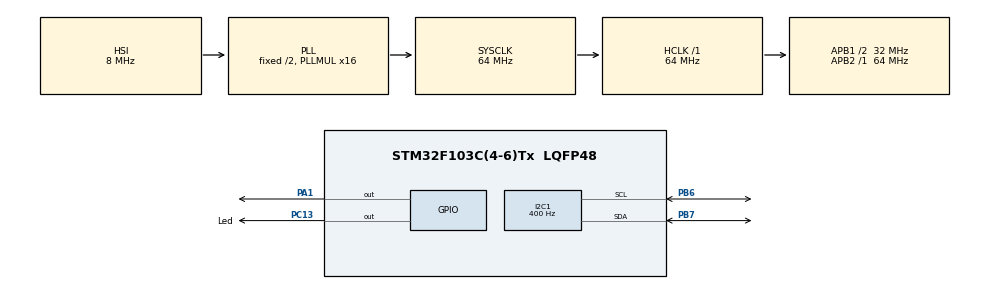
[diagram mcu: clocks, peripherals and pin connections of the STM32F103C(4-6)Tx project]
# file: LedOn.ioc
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I2C1.ClockSpeed=400
Mcu.Family=STM32F1
Mcu.Name=STM32F103C(4-6)Tx
Mcu.Package=LQFP48
NVIC.PriorityGroup=NVIC_PRIORITYGROUP_4
PA1.PinState=GPIO_PIN_SET
PA1.Signal=GPIO_Output
PB6.Mode=I2C
PB6.Signal=I2C1_SCL
PB7.Mode=I2C
PB7.Signal=I2C1_SDA
PC13-TAMPER-RTC.GPIO_Label=Led
PC13-TAMPER-RTC.GPIO_PuPd=GPIO_PULLUP
PC13-TAMPER-RTC.GPIO_Speed=GPIO_SPEED_FREQ_HIGH
PC13-TAMPER-RTC.PinState=GPIO_PIN_SET
PC13-TAMPER-RTC.Signal=GPIO_Output
ProjectManager.HeapSize=0x200
ProjectManager.StackSize=0x400
ProjectManager.TargetToolchain=MDK-ARM V5.32
RCC.AHBFreq_Value=64000000
RCC.APB1CLKDivider=RCC_HCLK_DIV2
RCC.APB1Freq_Value=32000000
RCC.APB1TimFreq_Value=64000000
RCC.APB2Freq_Value=64000000
RCC.APB2TimFreq_Value=64000000
RCC.HCLKFreq_Value=64000000
RCC.PLLMUL=RCC_PLL_MUL16
RCC.SYSCLKFreq_VALUE=64000000
RCC.SYSCLKSource=RCC_SYSCLKSOURCE_PLLCLK
RCC.USBFreq_Value=64000000
VP_SYS_VS_ND.Mode=No_Debug
board=custom

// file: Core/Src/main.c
/* USER CODE BEGIN Header */
/**
  ******************************************************************************
  * @file           : main.c
  * @brief          : Main program body
  ******************************************************************************
  * @attention
  *
  * Copyright (c) 2023 STMicroelectronics.
  * All rights reserved.
  *
  * This software is licensed under terms that can be found in the LICENSE file
  * in the root directory of this software component.
  * If no LICENSE file comes with this software, it is provided AS-IS.
  *
  ******************************************************************************
  */
/* USER CODE END Header */
#include "main.h"
#include "i2c.h"
#include "gpio.h"

void SystemClock_Config(void);

int main(void)
{

  /* MCU Configuration--------------------------------------------------------*/

  /* Reset of all peripherals, Initializes the Flash interface and the Systick. */
  HAL_Init();

  /* Configure the system clock */
  SystemClock_Config();

  /* Initialize all configured peripherals */
  MX_GPIO_Init();
  MX_I2C1_Init();

  /* Infinite loop */
  while (1)
  {

    /* USER CODE BEGIN 3 */
		HAL_Delay(1000);
		HAL_GPIO_WritePin(Led_GPIO_Port, Led_Pin, GPIO_PIN_RESET);
		HAL_Delay(1000);
		HAL_GPIO_WritePin(Led_GPIO_Port, Led_Pin, GPIO_PIN_SET);
  }
  /* USER CODE END 3 */
}

void SystemClock_Config(void)
{
  RCC_OscInitTypeDef RCC_OscInitStruct = {0};
  RCC_ClkInitTypeDef RCC_ClkInitStruct = {0};

  /** Initializes the RCC Oscillators according to the specified parameters
  * in the RCC_OscInitTypeDef structure.
  */
  RCC_OscInitStruct.OscillatorType = RCC_OSCILLATORTYPE_HSI;
  RCC_OscInitStruct.HSIState = RCC_HSI_ON;
  RCC_OscInitStruct.HSICalibrationValue = RCC_HSICALIBRATION_DEFAULT;
  RCC_OscInitStruct.PLL.PLLState = RCC_PLL_ON;
  RCC_OscInitStruct.PLL.PLLSource = RCC_PLLSOURCE_HSI_DIV2;
  RCC_OscInitStruct.PLL.PLLMUL = RCC_PLL_MUL16;
  if (HAL_RCC_OscConfig(&RCC_OscInitStruct) != HAL_OK)
  {
    Error_Handler();
  }

  /** Initializes the CPU, AHB and APB buses clocks
  */
  RCC_ClkInitStruct.ClockType = RCC_CLOCKTYPE_HCLK|RCC_CLOCKTYPE_SYSCLK
                              |RCC_CLOCKTYPE_PCLK1|RCC_CLOCKTYPE_PCLK2;
  RCC_ClkInitStruct.SYSCLKSource = RCC_SYSCLKSOURCE_PLLCLK;
  RCC_ClkInitStruct.AHBCLKDivider = RCC_SYSCLK_DIV1;
  RCC_ClkInitStruct.APB1CLKDivider = RCC_HCLK_DIV2;
  RCC_ClkInitStruct.APB2CLKDivider = RCC_HCLK_DIV1;

  if (HAL_RCC_ClockConfig(&RCC_ClkInitStruct, FLASH_LATENCY_2) != HAL_OK)
  {
    Error_Handler();
  }
}

void Error_Handler(void)
{
  __disable_irq();
  while (1)
  {
  }
}
